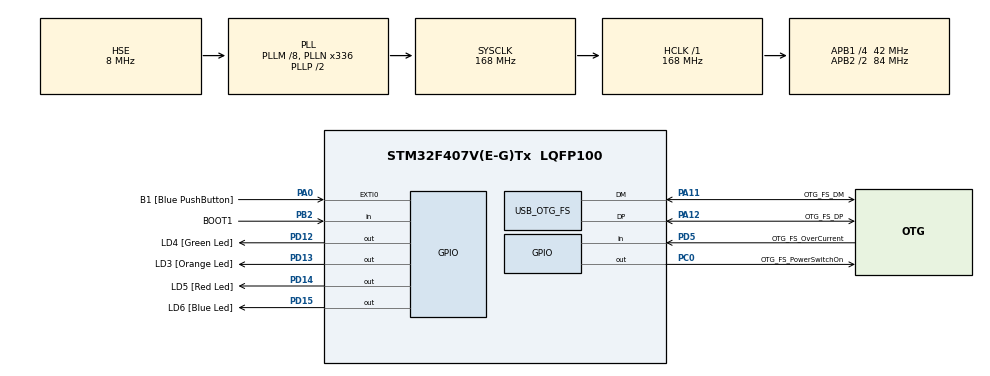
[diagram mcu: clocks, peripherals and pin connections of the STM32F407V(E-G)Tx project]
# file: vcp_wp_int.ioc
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Mcu.Family=STM32F4
Mcu.Name=STM32F407V(E-G)Tx
Mcu.Package=LQFP100
NVIC.EXTI0_IRQn=true\:1\:0\:true\:false\:true\:true\:true\:true
NVIC.OTG_FS_IRQn=true\:0\:0\:false\:false\:true\:true\:true\:true
NVIC.PriorityGroup=NVIC_PRIORITYGROUP_1
PA0-WKUP.GPIO_Label=B1 [Blue PushButton]
PA0-WKUP.GPIO_ModeDefaultEXTI=GPIO_MODE_IT_FALLING
PA0-WKUP.GPIO_PuPd=GPIO_NOPULL
PA0-WKUP.Signal=GPXTI0
PA10.GPIO_Label=OTG_FS_ID
PA10.GPIO_Mode=GPIO_MODE_AF_PP
PA10.GPIO_PuPd=GPIO_NOPULL
PA10.GPIO_Speed=GPIO_SPEED_FREQ_LOW
PA10.Signal=USB_OTG_FS_ID
PA11.GPIO_Label=OTG_FS_DM
PA11.GPIO_Mode=GPIO_MODE_AF_PP
PA11.GPIO_PuPd=GPIO_NOPULL
PA11.GPIO_Speed=GPIO_SPEED_FREQ_LOW
PA11.Mode=Device_Only
PA11.Signal=USB_OTG_FS_DM
PA12.GPIO_Label=OTG_FS_DP
PA12.GPIO_Mode=GPIO_MODE_AF_PP
PA12.GPIO_PuPd=GPIO_NOPULL
PA12.GPIO_Speed=GPIO_SPEED_FREQ_LOW
PA12.Mode=Device_Only
PA12.Signal=USB_OTG_FS_DP
PA13.GPIO_Label=SWDIO
PA13.Mode=Serial_Wire
PA13.Signal=SYS_JTMS-SWDIO
PA14.GPIO_Label=SWCLK
PA14.Mode=Serial_Wire
PA14.Signal=SYS_JTCK-SWCLK
PA9.GPIO_Label=VBUS_FS
PA9.GPIO_Mode=GPIO_MODE_INPUT
PA9.GPIO_PuPd=GPIO_NOPULL
PA9.Signal=USB_OTG_FS_VBUS
PB2.GPIO_Label=BOOT1
PB2.GPIO_Mode=GPIO_MODE_INPUT
PB2.GPIO_PuPd=GPIO_NOPULL
PB2.Signal=GPIO_Input
PB3.GPIO_Label=SWO
PB3.Signal=SYS_JTDO-SWO
PC0.GPIO_Label=OTG_FS_PowerSwitchOn
PC0.GPIO_PuPd=GPIO_NOPULL
PC0.GPIO_Speed=GPIO_SPEED_FREQ_LOW
PC0.PinState=GPIO_PIN_SET
PC0.Signal=GPIO_Output
PC14-OSC32_IN.GPIO_Label=PC14-OSC32_IN
PC14-OSC32_IN.Mode=LSE-External-Oscillator
PC14-OSC32_IN.Signal=RCC_OSC32_IN
PC15-OSC32_OUT.GPIO_Label=PC15-OSC32_OUT
PC15-OSC32_OUT.Mode=LSE-External-Oscillator
PC15-OSC32_OUT.Signal=RCC_OSC32_OUT
PD12.GPIO_Label=LD4 [Green Led]
PD12.GPIO_PuPd=GPIO_NOPULL
PD12.GPIO_Speed=GPIO_SPEED_FREQ_LOW
PD12.Signal=GPIO_Output
PD13.GPIO_Label=LD3 [Orange Led]
PD13.GPIO_PuPd=GPIO_NOPULL
PD13.GPIO_Speed=GPIO_SPEED_FREQ_LOW
PD13.Signal=GPIO_Output
PD14.GPIO_Label=LD5 [Red Led]
PD14.GPIO_PuPd=GPIO_NOPULL
PD14.GPIO_Speed=GPIO_SPEED_FREQ_LOW
PD14.Signal=GPIO_Output
PD15.GPIO_Label=LD6 [Blue Led]
PD15.GPIO_PuPd=GPIO_NOPULL
PD15.GPIO_Speed=GPIO_SPEED_FREQ_LOW
PD15.Signal=GPIO_Output
PD5.GPIO_Label=OTG_FS_OverCurrent
PD5.GPIO_Mode=GPIO_MODE_INPUT
PD5.GPIO_PuPd=GPIO_NOPULL
PD5.Signal=GPIO_Input
PH0-OSC_IN.GPIO_Label=PH0-OSC_IN
PH0-OSC_IN.Mode=HSE-External-Oscillator
PH0-OSC_IN.Signal=RCC_OSC_IN
PH1-OSC_OUT.GPIO_Label=PH1-OSC_OUT
PH1-OSC_OUT.Mode=HSE-External-Oscillator
PH1-OSC_OUT.Signal=RCC_OSC_OUT
ProjectManager.HeapSize=0x200
ProjectManager.StackSize=0x400
ProjectManager.TargetToolchain=STM32CubeIDE
RCC.48MHZClocksFreq_Value=48000000
RCC.AHBFreq_Value=168000000
RCC.APB1CLKDivider=RCC_HCLK_DIV4
RCC.APB1Freq_Value=42000000
RCC.APB1TimFreq_Value=84000000
RCC.APB2CLKDivider=RCC_HCLK_DIV2
RCC.APB2Freq_Value=84000000
RCC.APB2TimFreq_Value=168000000
RCC.CortexFreq_Value=168000000
RCC.HCLKFreq_Value=168000000
RCC.HSE_VALUE=8000000
RCC.HSI_VALUE=16000000
RCC.PLLM=8
RCC.PLLN=336
RCC.PLLQ=7
RCC.SYSCLKFreq_VALUE=168000000
RCC.SYSCLKSource=RCC_SYSCLKSOURCE_PLLCLK
RCC.VCOOutputFreq_Value=336000000
USB_DEVICE.CLASS_NAME_FS=CDC
USB_DEVICE.VirtualMode-CDC_FS=Cdc
USB_DEVICE.VirtualModeFS=Cdc_FS
USB_OTG_FS.VirtualMode=Device_Only
VP_USB_DEVICE_VS_USB_DEVICE_CDC_FS.Mode=CDC_FS
board=STM32F407G-DISC1

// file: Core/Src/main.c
/* USER CODE BEGIN Header */
/**
  ******************************************************************************
  * @file           : main.c
  * @brief          : Main program body
  ******************************************************************************
  * @attention
  *
  * Copyright (c) 2024 STMicroelectronics.
  * All rights reserved.
  *
  * This software is licensed under terms that can be found in the LICENSE file
  * in the root directory of this software component.
  * If no LICENSE file comes with this software, it is provided AS-IS.
  *
  ******************************************************************************
  */
/* USER CODE END Header */
#include "main.h"
#include "usb_device.h"

/* USER CODE BEGIN PV */
static float speed;
static uint32_t last_update;
/* USER CODE END PV */

void SystemClock_Config(void);
static void MX_GPIO_Init(void);
/* USER CODE BEGIN PFP */
float getSpeed();
void updateSpeed(float new_speed);
/* USER CODE END PFP */

int main(void)
{

  /* MCU Configuration--------------------------------------------------------*/

  /* Reset of all peripherals, Initializes the Flash interface and the Systick. */
  HAL_Init();

  /* Configure the system clock */
  SystemClock_Config();

  /* Initialize all configured peripherals */
  MX_GPIO_Init();
  MX_USB_DEVICE_Init();

  /* Infinite loop */
  /* USER CODE BEGIN WHILE */
  speed = 0;
  last_update = HAL_GetTick();
  while (1)
  {
    /* USER CODE END WHILE */
    uint32_t cur_time = HAL_GetTick();
    if (cur_time - last_update > 7000) {
      speed = 0;
    }
  }
}

void SystemClock_Config(void)
{
  RCC_OscInitTypeDef RCC_OscInitStruct = {0};
  RCC_ClkInitTypeDef RCC_ClkInitStruct = {0};

  /** Configure the main internal regulator output voltage
  */
  __HAL_RCC_PWR_CLK_ENABLE();
  __HAL_PWR_VOLTAGESCALING_CONFIG(PWR_REGULATOR_VOLTAGE_SCALE1);

  /** Initializes the RCC Oscillators according to the specified parameters
  * in the RCC_OscInitTypeDef structure.
  */
  RCC_OscInitStruct.OscillatorType = RCC_OSCILLATORTYPE_HSE;
  RCC_OscInitStruct.HSEState = RCC_HSE_ON;
  RCC_OscInitStruct.PLL.PLLState = RCC_PLL_ON;
  RCC_OscInitStruct.PLL.PLLSource = RCC_PLLSOURCE_HSE;
  RCC_OscInitStruct.PLL.PLLM = 8;
  RCC_OscInitStruct.PLL.PLLN = 336;
  RCC_OscInitStruct.PLL.PLLP = RCC_PLLP_DIV2;
  RCC_OscInitStruct.PLL.PLLQ = 7;
  if (HAL_RCC_OscConfig(&RCC_OscInitStruct) != HAL_OK)
  {
    Error_Handler();
  }

  /** Initializes the CPU, AHB and APB buses clocks
  */
  RCC_ClkInitStruct.ClockType = RCC_CLOCKTYPE_HCLK|RCC_CLOCKTYPE_SYSCLK
                              |RCC_CLOCKTYPE_PCLK1|RCC_CLOCKTYPE_PCLK2;
  RCC_ClkInitStruct.SYSCLKSource = RCC_SYSCLKSOURCE_PLLCLK;
  RCC_ClkInitStruct.AHBCLKDivider = RCC_SYSCLK_DIV1;
  RCC_ClkInitStruct.APB1CLKDivider = RCC_HCLK_DIV4;
  RCC_ClkInitStruct.APB2CLKDivider = RCC_HCLK_DIV2;

  if (HAL_RCC_ClockConfig(&RCC_ClkInitStruct, FLASH_LATENCY_5) != HAL_OK)
  {
    Error_Handler();
  }
}

static void MX_GPIO_Init(void)
{
  GPIO_InitTypeDef GPIO_InitStruct = {0};

  /* GPIO Ports Clock Enable */
  __HAL_RCC_GPIOC_CLK_ENABLE();
  __HAL_RCC_GPIOH_CLK_ENABLE();
  __HAL_RCC_GPIOA_CLK_ENABLE();
  __HAL_RCC_GPIOB_CLK_ENABLE();
  __HAL_RCC_GPIOD_CLK_ENABLE();

  /*Configure GPIO pin Output Level */
  HAL_GPIO_WritePin(OTG_FS_PowerSwitchOn_GPIO_Port, OTG_FS_PowerSwitchOn_Pin, GPIO_PIN_SET);

  /*Configure GPIO pin Output Level */
  HAL_GPIO_WritePin(GPIOD, LD4_Pin|LD3_Pin|LD5_Pin|LD6_Pin, GPIO_PIN_RESET);

  /*Configure GPIO pin : OTG_FS_PowerSwitchOn_Pin */
  GPIO_InitStruct.Pin = OTG_FS_PowerSwitchOn_Pin;
  GPIO_InitStruct.Mode = GPIO_MODE_OUTPUT_PP;
  GPIO_InitStruct.Pull = GPIO_NOPULL;
  GPIO_InitStruct.Speed = GPIO_SPEED_FREQ_LOW;
  HAL_GPIO_Init(OTG_FS_PowerSwitchOn_GPIO_Port, &GPIO_InitStruct);

  /*Configure GPIO pin : B1_Pin */
  GPIO_InitStruct.Pin = B1_Pin;
  GPIO_InitStruct.Mode = GPIO_MODE_IT_FALLING;
  GPIO_InitStruct.Pull = GPIO_NOPULL;
  HAL_GPIO_Init(B1_GPIO_Port, &GPIO_InitStruct);

  /*Configure GPIO pin : BOOT1_Pin */
  GPIO_InitStruct.Pin = BOOT1_Pin;
  GPIO_InitStruct.Mode = GPIO_MODE_INPUT;
  GPIO_InitStruct.Pull = GPIO_NOPULL;
  HAL_GPIO_Init(BOOT1_GPIO_Port, &GPIO_InitStruct);

  /*Configure GPIO pins : LD4_Pin LD3_Pin LD5_Pin LD6_Pin */
  GPIO_InitStruct.Pin = LD4_Pin|LD3_Pin|LD5_Pin|LD6_Pin;
  GPIO_InitStruct.Mode = GPIO_MODE_OUTPUT_PP;
  GPIO_InitStruct.Pull = GPIO_NOPULL;
  GPIO_InitStruct.Speed = GPIO_SPEED_FREQ_LOW;
  HAL_GPIO_Init(GPIOD, &GPIO_InitStruct);

  /*Configure GPIO pin : OTG_FS_OverCurrent_Pin */
  GPIO_InitStruct.Pin = OTG_FS_OverCurrent_Pin;
  GPIO_InitStruct.Mode = GPIO_MODE_INPUT;
  GPIO_InitStruct.Pull = GPIO_NOPULL;
  HAL_GPIO_Init(OTG_FS_OverCurrent_GPIO_Port, &GPIO_InitStruct);

  /* EXTI interrupt init*/
  HAL_NVIC_SetPriority(EXTI0_IRQn, 1, 0);
  HAL_NVIC_EnableIRQ(EXTI0_IRQn);

}

void Error_Handler(void)
{
  __disable_irq();
  while (1)
  {
  }
}

float getSpeed() {
  return speed;
}

void updateSpeed(float new_speed) {
  speed = new_speed;
  last_update = HAL_GetTick();
}
